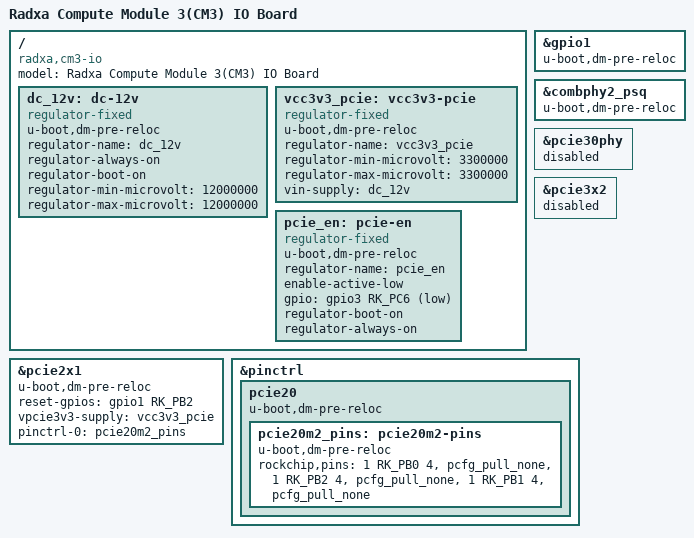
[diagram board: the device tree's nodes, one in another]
// SPDX-License-Identifier: (GPL-2.0+ OR MIT)
/*
 * Copyright (c) 2020 Rockchip Electronics Co., Ltd.
 * Copyright (c) 2021 Radxa Limited.
 *
 */

/dts-v1/;

#include "rk3566-radxa-cm3.dtsi"

/ {
	model = "Radxa Compute Module 3(CM3) IO Board";
	compatible = "radxa,cm3-io", "radxa,cm3", "rockchip,rk3566";

	dc_12v: dc-12v {
		u-boot,dm-pre-reloc;
		compatible = "regulator-fixed";
		regulator-name = "dc_12v";
		regulator-always-on;
		regulator-boot-on;
		regulator-min-microvolt = <12000000>;
		regulator-max-microvolt = <12000000>;
	};

	vcc3v3_pcie: vcc3v3-pcie {
		u-boot,dm-pre-reloc;
		compatible = "regulator-fixed";
		regulator-name = "vcc3v3_pcie";
		regulator-min-microvolt = <3300000>;
		regulator-max-microvolt = <3300000>;
		vin-supply = <&dc_12v>;
	};

	pcie_en: pcie-en {
		u-boot,dm-pre-reloc;
		compatible = "regulator-fixed";
		regulator-name = "pcie_en";
		enable-active-low;
		gpio = <&gpio3 RK_PC6 GPIO_ACTIVE_LOW>;
		regulator-boot-on;
		regulator-always-on;
	};
};

&gpio1 {
	u-boot,dm-pre-reloc;
	status = "okay";
};

&pcie2x1 {
	u-boot,dm-pre-reloc;
	status = "okay";
	reset-gpios = <&gpio1 RK_PB2 GPIO_ACTIVE_HIGH>;
	vpcie3v3-supply = <&vcc3v3_pcie>;
	pinctrl-0 = <&pcie20m2_pins>;
};

&combphy2_psq {
	u-boot,dm-pre-reloc;
	status = "okay";
};

&pcie30phy {
	status = "disabled";
};

&pcie3x2 {
	status = "disabled";
};

&pinctrl {

	pcie20 {
		u-boot,dm-pre-reloc;

		pcie20m2_pins: pcie20m2-pins {
			u-boot,dm-pre-reloc;
			rockchip,pins =
				/* pcie20_clkreqnm2 */
				<1 RK_PB0 4 &pcfg_pull_none>,
				/* pcie20_perstnm2 */
				<1 RK_PB2 4 &pcfg_pull_none>,
				/* pcie20_wakenm2 */
				<1 RK_PB1 4 &pcfg_pull_none>;
		};
	};
};
